# nrf7140_wificore register map
Vendor: Nordic Semiconductor; Series: nRF71; File version: 1
Registers are 32-bit, read-write, reset 0x0 unless marked. A register's access mark holds for its fields unless they carry their own. Offsets are from the block's base; [hi:lo] are bit positions; lines under a group give offsets from that group; {n}, {i} and the like mark numbered series; 'fields as' and 'values as' point back to an identical list; <NAME> marks a mode.

## RPUSYS (part 2 of 3) — RPUPBUS
Base 0x48080000; alternate view of RPUMAC
0x6000 EDC_PERIP group — Unspecified
  {0x0+0x20*j} EDCPERIPCHANREGS[{j}] (j=0..63) group — Unspecified
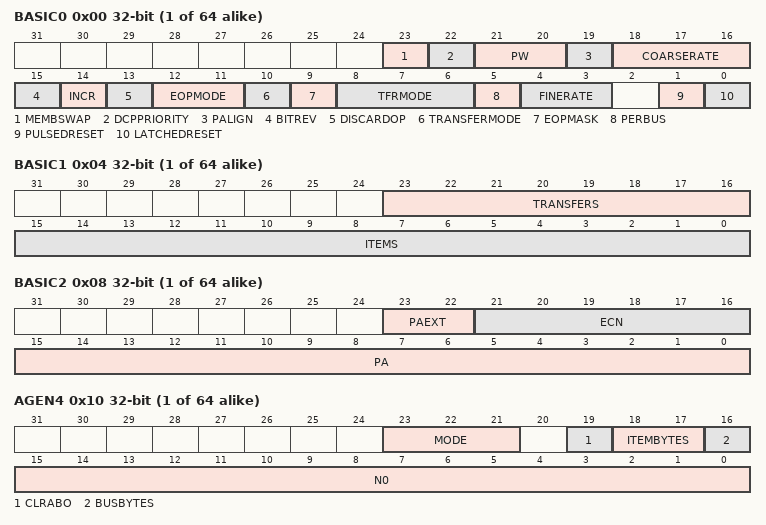
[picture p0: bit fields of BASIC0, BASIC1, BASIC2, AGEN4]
    0x00 BASIC0 — Description cluster: EDC PERIP BASIC0
      [23] MEMBSWAP — Big/little endian byte swap.If set, byte order will be reversed in all memory read/write transfers.MEM_BSWAP is applied on 24-bit GRAM or 32-bit External RAM memory accesses.MEM_BSWAP is applied on the memory word after the peripheral data to transfer has been packed, or on the memory word read from RAM before it is unpacked for transfer to the peripheral.Note : Applied to both source and destination memory transfers.
      [22] DCPPRIORITY — Specifies the priority of DCP thread execution:
        0=LowPriorityDcpThread; 1=High priority DCP thread (use for realtime peripherals such as the SCP)
      [21:20] PW — Specifies the width of the peripheral transfer.If transfers are being performed on the wide Tbus then parallel transfers of this width take place.
        0=8BitPbusOrTbus; 1=16BitPbusOrTbus; 2=24BitPbusOrTbus; 3=32BitSysbus
      [19] PALIGN — Specifies the alignment of peripheral data:
        0=DataIsRightAligned; 1=DataIsLeftAligned
      [18:16] COARSERATE — COARSE_RATE defines the rate at which EDC_BURST_LENGTH byte bursts may be transferred on this channel.0 : CR = 1 / 81 : CR = 1 / 162 : CR = 1 / 323 : CR = 1 / 644 : CR = 1 / 1285 : CR = 1 / 2566 : CR = 1 / 5127 : CR = 1 / 1024FR bursts every CR sysclk periods, giving (sysclk * EDC_BURST_LENGTH * FR * CR) bytes / sec)Notes:1. If COARSE_RATE=0 and FINE_RATE=0 then the burst rate is not controlled.2. COARSE_RATE is unused for TFR_MODE=100,101, where the COARSE_RATE for the ECN linked channel with TFR_MODE=001,011 is used once for both transfers.
      [15] BITREV — Specifies bit reversal within transferred bytes:0 : Bytes are not bit reversed1 : Bytes are bit reversedNotes :1. Applied to destination transfers only.2. Just the parameter for the destination channel is used when linked using ECN.
      [14] INCR — Specifies incrementing peripheral address burst mode.By default all operations to the peripheral are to a single register location.Note: Only applicable to SysBus or PBus transfers.
        0=Static peripheral address defined by PA.Typically used when transferring to/from a FIFO mapped to a single data port peripheral address; 1=Incrementing peripheral address, start address defined by PA. Typically used when transferring to a block of configuration registers.
      [13] DISCARDOP — Controls whether output of transfers should be discarded:0 : Output not discarded.1 : Output discarded, transfers otherwise operate as normal.Notes:1. this control cannot be used for 'to EDC channel (ECN)' transfers where it should instead be set for the 'from EDC channel (ECN)' transfer.2. this register is double buffered at start of job.
      [12:11] EOPMODE — Specifies the end of packet mode:Notes: 1. When enabled, EOP signal terminates all TRANSFERS, not just ITEMS within current transfer.
        0=DMA job completes after TRANSFERS*ITEMS transfers; 1=Reserve (This is reserved.); 2=DmaJobCompletesAfter2 (DMA job completes after TRANSFERS*ITEMS transfers, or on receipt of EOP signal from peripheral, whichever occurs first.); 3=Reserve3 (This is reserved.)
      [10] TRANSFERMODE — Selects multiple 16-bit items length or single 24-bit items length transfer:0 : Perform TRANSFERS * ITEMS item transfers.1 : Perform single '(TRANSFERS << 16) | ITEMS' item transfer.Notes:1. TRANSFERS_MODE must be written before writing TRANSFERS and ITEMS to BASIC1.2. TRANSFERS will always return 1 after switching TRANSFERS_MODE from 1 to 0.3. Single 24-bit items length transfer supported only when address generator is in row-column mode. Note that row-column mode is available only when EDC_SYS_CONFIGURATION_STATUS[0] = '1'; therefore 24-bit items transferis supported only when EDC_SYS_CONFIGURATION_STATUS[0] = '1'.The required row-column parameters to have modulo addressing are N0=anything that divides N2 and such that N0 >= GRAM_REQS-1 (the second condition is required to have best performance), N1=1, N2=modulo, A=0, B=0, O=start index.
      [9] EOPMASK — Selects the mask for the last memory write in case of EOP:
        0=Mask from address generator is used; 1=Mask from TBus read port is used
      [8:6] TFRMODE — 000 : Read from memory (MA+agenOffset), write to peripheral (PA+incrOffset)001 : Read from memory(MA+agenOffset), write to EDC channel (ECN)010 : Read from peripheral (PA+incrOffset), write to memory (MA+agenOffset)011 : Read from peripheral (PA+incrOffset), write to EDC channel (ECN)100 : Read from EDC channel (ECN), write to memory (MA+agenOffset)101 : Read from EDC channel (ECN), write to peripheral (PA+incrOffset)110 : Read FDSG/LFSR/PRBS offsets from MMR (MA+[0:3]), write to transfer bus (TBus)111 : Read from peripheral (PA+incrOffset), write to peripheral (MA+incr2Offset)Notes: 1. ITEMS must match for peripheral to peripheral transfers.2. Partial address masks only supported at end of transfers.3. 'from EDC channel (ECN)' transfers should be configured/started before 'to EDC channel (ECN)' transfers.4. ITEM_BYTES must be set to 3 bytes for TFR_MODE=110
      [5] PERBUS — Selects bus for peripheral transfers:0 : Peripheral transfer is carried over the transfer bus (TBus) using hardware flow control of peripheral accesses.1 : Peripheral transfer is carried over the non-stalling peripheral bus (SysBus or PBus) using (PA + incrOffset) as the peripheral addressNotes:1. Must be set to 0 when TFR_MODE=110.2. Must be set to 1 when PW=11.
      [4:3] FINERATE — COARSE_RATE and FINE_RATE together define the rate at which EDC_BURST_LENGTH byte bursts may be transferred on this channel.0 : FR = 71 : FR = 62 : FR = 53 : FR = 4FR bursts every CR sysclk periods, giving (sysclk * EDC_BURST_LENGTH * FR * CR) bytes / sec)Notes:1. If COARSE_RATE=0 and FINE_RATE=0 then the burst rate is not controlled.2. COARSE_RATE is unused for TFR_MODE=100,101, where the COARSE_RATE for the ECN linked channel with TFR_MODE=001,011 is used once for both transfers.
      [1] PULSEDRESET — Pulsed channel transfer engine software reset, clears automatically at start of next transfer on channel.Note: Once set must remain high before a DCP start/run instruction, so if set before ldbasic/ldfull it must be set again by the ldbasic/ldfull before the start/run.
      [0] LATCHEDRESET — Latched transfer engine channel software reset.Note: Use of PULSED_RESET is preferred over LATCHED_RESET.
    0x04 BASIC1 — Description cluster: EDC PERIP BASIC1
      [23:16] TRANSFERS — When TRANSFERS_MODE=0:The number of DMA transfers in the DMA job, represented in 'natural' format (TRANSFERS=1 specifies one transfer).TRANSFERS = 0 selects a different mode of operation -Skip the number of items defined by ITEMS, then generate one item without updating the state of the address generator.This mode is used for applying error correction to the Outer Decoder input data.When TRANSFERS_MODE=1:ITEMS[23:0] (TRANSFERS is internally fixed at 1).Note: when EOP_MODE = '10', TRANSFERS > 1 is not supported.
      [15:0] ITEMS — The number of items in each DMA transfer, represented in 'natural' format (ITEMS=1 gives one transfer).The total number of items in a DMA job is (TRANSFERS * ITEMS).If transferring to/from TBus peripherals, (ITEM_BYTES+1)*ITEMS must be divisible by (PW+1)*PERIP_NUM, with any surplus being discarded, and whilst a byte mask isprovided to TBus peripherals to indicate shortfall few peripherals make use of this.Decremented by 'ITEM_BYTES+1'.Note: This register is double buffered at start of job.
    0x08 BASIC2 — Description cluster: EDC PERIP BASIC2
      [23:22] PAEXT — Extended PA address bit.
      [21:16] ECN — When TFR_MODE=000 ... 110 :EDC channel number to connect with for memory-to-memory transferNote: When linking channels using ECN the ITEMS setting for each channel must match, though TRANSFERS need not be the same.This hardware restriction arises because each transfer consists of a sequence of EDC_BURST_LENGTH byte bursts,with one final burst which carries the number of bytes required to complete the transfer.The number of bytes in the final burst of a transfer is rem(ITEMS * (ITEM_BYTES+1), EDC_BURST_LENGTH).When TFR_MODE=111 :ECN[4:3]=PW_2 : Specifies the width of the destination peripheral transfer.If transfers are being performed on the wide Tbus then parallel transfers of this width take place.00 : 8 bit(PBus or TBus)01 : 16 bit (PBus or TBus)10 : 24 bit (PBus or TBus)11 : 32 bit (SysBus)ECN[2]=PALIGN_2 : Specifies the alignment of destination peripheral data:0 : Data is right aligned1 : Data is left alignedECN[1]=INCR_2 : Specifies incrementing destination peripheral address burst mode.By default all operations to the destination peripheral are to a single register location.0 : Static destination peripheral address defined by MA.Typically used when transferring to a FIFO mapped to a single data port destination peripheral address.1 : Incrementing destination peripheral address, start address defined by MA. Typically used when transferring to a block of configuration registers.Note: Only applicable to SysBus or PBus transfers.ECN[0]=PER_BUS_2 : Selects bus for destination peripheral transfers:0 : Destination peripheral transfer is carried over the transfer bus (TBus) using hardware flow control of destination peripheral accesses.1 : Destination peripheral transfer is carried over the non-stalling peripheral bus (SysBus or PBus) using (MA + incr2Offset) as the destination peripheral address
      [15:0] PA — For transfers over the non-stalling peripheral bus (SysBus or PBus), PA specifies the base peripheral address.For transfers over the stalling transfer bus (TBus), PA[13:0] selects the port ID within the following TBus read/write port selection groups:PA[15:14]=00 : Peripheral TBus write ports.PA[15:14]=01 : EDC Address Generator Offset write ports.PA[15:14]=10 : Peripheral TBus read portsNotes:1. INCR=1 produces a sequence of incrementing addressesPA, PA+1, PA+2, ...2. Address generator offset TBus write requests must be allocated to a higher priority (lower number) EDC channelthan the EDC channel address generator that they are feeding.3. Address generator offset TBus write requests EDC channel must be started before the EDC channel address generator that they are feeding.
    0x0C BASIC3 — Description cluster: EDC PERIP BASIC3
      [23:0] MA — When TFR_MODE=000 ... 110 :Memory Address defines the base address of the memory transfers controlled by this DMA channel.The units of MA are physical RAM locations, and the physical RAM bus targetted by this DMA channel is selected by BUS_BYTES. The byte address of the memory base in the chosen RAM space is MA * BUS_BYTES.When TFR_MODE=111 :For transfers over the non-stalling peripheral bus (SysBus or PBus), MA specifies the base peripheral address.For transfers over the stalling transfer bus (TBus), MA[13:0] selects the port ID within the following TBus write port selection groups:MA[15:14]=00 : Peripheral TBus write ports.MA[15:14]=01 : EDC Address Generator Offset write ports.Notes:1. INCR=1 produces a sequence of incrementing addressesMA, MA+1, MA+2, ... (where MA is shadowed for transfer rather than current MA used by DCP)2. Address generator offset TBus write requests must be allocated to a higher priority (lower number) EDC channelthan the EDC channel address generator that they are feeding.3. Address generator offset TBus write requests EDC channel must be started before the EDC channel address generator that they are feeding.4. This register is double buffered at start of job.
    0x10 AGEN4 — Description cluster: EDC PERIP AGEN4
      [23:21] MODE — Note: If EDC_SYS_CONFIGURATION_STATUS[0] = '0', only modulo mode is supported.
        0=Modulo; 1=RepeatSkip; 2=RowColumn; 3=TwistedRowColumn; 4=BurstRowColumn; 5=Fifo; 6=RunLength; 7=RowColCd
      [19] CLRABO — Setting CLR=1 clears the internal registers a, b and o in the address generator for this channel.This register clears automatically.
      [18:17] ITEMBYTES — The number of bytes in each item of the data structure accessed by the address generator.0 : 1 byte1 : 2 bytes2 : 3 bytes3 : 4 bytesNotes:1. This must be programmed correctly even when the address generator is not in use.2. This register is double buffered at start of job.
      [16] BUSBYTES — The byte width of the memory bus targetted by the address generator.Note: this register is double buffered at start of job.
        0=3BytesGlobalRamBus; 1=4 bytes (external RAM bus)
      [15:0] N0 — Address generator N0 parameter.Use depends on selected mode:Modulo mode : modulo (0 value gives 2^16 modulo)Repeat-skip mode: number of items in one sequenceRow-column mode : number of items in one block (rows * columns)Twisted row-column mode : number of items in one burstBurst row-column mode : number of items in one burstFIFO mode : number of items in one burst (one burst for each FIFO )Run-length mode : number of items to skip after one 'run'Row-column-CD mode: number of FIFOs
    0x14 AGEN5 — Description cluster: EDC PERIP AGEN5
      [23:0] N1 — Address generator N1 parameter.Use depends on EDC_SYS_CONFIGURATION_STATUS register and OFFSET_ADD field of EDC_PERIP_JOB0 register:If EDC_SYS_CONFIGURATION_STATUS[1] = '1' and OFFSET_ADD = '1' then only 10 LSBs are used and it represents the LUT read pointer. Automatically incremented. When LUT are used, address generator increment is not needed.Else use depends on selected mode:Modulo mode : increment per itemRepeat-skip mode: number of repeats of each sequenceRow-column mode : number of rowsTwisted row-column mode : number of rowsBurst row-column mode : number of rowsFIFO mode : number of FIFOsRun-length mode : unusedRow-column-CD mode: rem((d1-d0) * numFifos + buffLen, buffLen), where d0 is the delay of FIFO 0 and d1 is the delay of FIFO 1, both measured in itemsNotes:1. If EDC_SYS_CONFIGURATION_STATUS[1] = '1', this register is double buffered (only 10 LSBs) at start of job, to allow reconfiguration of LUT read pointer while job is still active.2. If EDC_SYS_CONFIGURATION_STATUS[1:0] = '00', this register is not present and the increment per item if fixed to 1.
    0x18 AGEN6 — Description cluster: EDC PERIP AGEN6
      [23:0] N2 — Address generator N2 parameter.Use depends on selected mode:Modulo mode : if AGEN_STATE_B[0]=0, start index (must be in the range 0 to N0-1), else unusedRepeat-skip mode: number of items from the start of one sequence to the start of the next sequenceRow-column mode : number of items in the set of blocks (rows * columns * blocks)Twisted row-column mode : number of items in one block(rows * columns)Burst row-column mode : number of items in one block minus number of items in one burst(rows * columns - N0)FIFO mode : number of items in the whole FIFO structureRun-length mode : unusedRow-column-CD mode: number of items in the CD buffer.Note: N2 must be an integer multiple of abs(d1-d0) * numFifos, where d0 is the delay of FIFO 0 and d1 is the delay of FIFO 1, both measured in itemsIf OFFSET_ADD is in use and EDC_SYS_CONFIGURATION_STATUS[1] = '1', N2 can be set to enforce a modulo on the LUT read pointer.Notes:1. This register is double buffered at start of job.2. If EDC_SYS_CONFIGURATION_STATUS[0] = '0', only 16 LSBs are used.
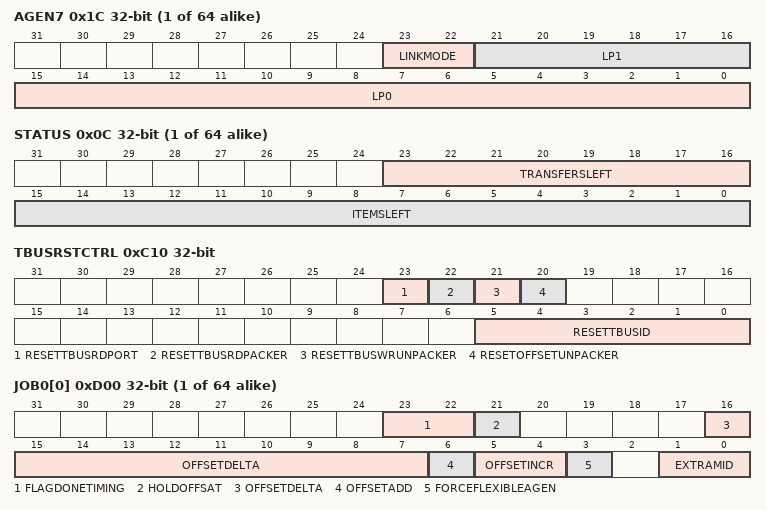
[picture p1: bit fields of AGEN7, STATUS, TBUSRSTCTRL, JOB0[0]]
    0x1C AGEN7 — Description cluster: EDC PERIP AGEN7
      [23:22] LINKMODE — Controls pairing of even numbered write channel 'N' and odd numbered read channel 'N+1':00 : Pairing disabled01 : Pair using FIFO mode10 : Pair using BLOCK mode11 : reservedNotes:1. Linked channels must have the same ITEM_BYTES configuration.2. LINK_MODE must be disabled on channels with EXT_RAM_READ_AHEAD set to 1(but can be set on channels ECN linked to these that have EXT_RAM_READ_AHEAD set to 0).3. Changing LINK_MODE setting causes read and write buffer counts to be reset.4. If EDC_SYS_CONFIGURATION_STATUS[0] = '0', the pairing is not supported.
      [21:16] LP1 — FIFO mode: not usedBLOCK mode : maxBlocks - the maximum number of blocks in a paired buffer
      [15:0] LP0 — FIFO mode: maxItems - the maximum number of items in a paired bufferNote: If read ITEMS is not equal to write ITEMS then LP0 must be >= 2 * EDC_BURST_LENGTHBLOCK mode : itemsPerBlock - the number of items in a block
  {0x800+0x10*j} EDCPERIPCTXTREGS[{j}] (j=0..63) group — Unspecified
    0x00 AGENCONTEXT0 — Description cluster: EDC PERIP AGEN CONTEXT0
      [15:0] AGENSTATEA — Address generator A variable.If this register is loaded by the DCP then it should be fenced using LDBASIC/LDFULL before the RUN instruction.
    0x04 AGENCONTEXT1 — Description cluster: EDC PERIP AGEN CONTEXT1
      [15:0] AGENSTATEB — Address generator B variable.If MODE=0 (modulo mode) AGEN_STATE_B[0]=1 causes N2 to be substituted with offsets fed from another channel.If AGEN_STATE_B[0]=1, N1 must be different than 1 to prevent linear mode logic to be enabled, since it does not support offset addition.If this register is loaded by the DCP then it should be fenced using LDBASIC/LDFULL before the RUN instruction.
    0x08 AGENCONTEXT2 — Description cluster: EDC PERIP AGEN CONTEXT2
      [23:0] AGENSTATEO — Address generator O variable.If this register is loaded by the DCP then it should be fenced using LDBASIC/LDFULL before the RUN instruction.
    0x0C STATUS — Description cluster: EDC PERIP STATUS
      [23:16] TRANSFERSLEFT — When TRANSFERS_MODE=0:The number of DMA transfers remaining in the DMA job, represented in 'natural' format.When TRANSFERS_MODE=1:ITEMS_LEFT[23:0].
      [15:0] ITEMSLEFT — The number of items remaining in each DMA transfer, represented in 'natural' format.Note: This is updated to represent the number of items completed when a job completes for EOP_MODE=10.
  0xC00 EDCGPIO0OUT
    [15:0] GPIO0OUT — Value output on bits 15:0 of UCCP top level GPIO_OUT pins.
  0xC04 EDCGPIO1OUT
    [15:0] GPIO1OUT — Value output on bits 31:16 of UCCP top level GPIO_OUT pins.
  0xC08 EDCGPIO0IN ro
    [15:0] GPIO0IN — Value input on bits 15:0 of UCCP top level GPIO_IN pins.
  0xC0C EDCGPIO1IN ro
    [15:0] GPIO1IN — Value input on bits 31:16 of UCCP top level GPIO_IN pins.
  0xC10 TBUSRSTCTRL — EDC PERIP TBUS RST CTRL
    [23] RESETTBUSRDPORT — Reset TBus read port data held for next transfer.
    [22] RESETTBUSRDPACKER — Reset TBus read packer.
    [21] RESETTBUSWRUNPACKER — Reset TBus write unpacker.
    [20] RESETOFFSETUNPACKER — Reset Address Generator Offset unpacker.
    [5:0] RESETTBUSID — Port ID of TBus to reset.
  0xC14 PERFCTRL — EDC PERIP PERF CTRL
    [23] EXTRAMREADAHEAD — 0 : Do not read-ahead from ExtRAM (appropriate setting for multi-channel ExtRAM reads).1 : Read-ahead from ExtRAM (appropriate setting for single-channel ExtRAM reads or multi-channel only where each channel has a unique EXT_RAM_ID in range 0 to EDC_EXT_RAM_REQS-1).For use in high read latency ExtRAM systems, should not be used in low latency ExtRAM systems as can reduce performance due to additional destination address generation latency.When enabled, address generator modes that make use of offsets (run-length, twisted-row-col, FIFO) are not supported for ExtRAM or GRAM TFR_MODE=4 destination transfer from an ExtRAM source TFR_MODE=1 transfer.ExtRAM-to-ExtRAM transfers are not supported when enabled.
  0xC18 EDCSCPCTRL
    [11:0] EDCSCPKICK — EDC_SCP_KICK[n]=1 causes update of SET_ADC_POWER/SET_SCP_POWER/NEW_ADC_POWER/NEW_SCP_POWER/INPUT_I/INPUT_Q registers within SCP[n] when SCP_CONTROL2[n].SCP_KICK_ENABLE=1.Register auto-clears.
  0xC1C EDCDCPBASEADDR
    [23:0] DCPBASEADDR — Base address of combined DCP code image (for use by debugger).
  0xC20 WLANRXCTRL — EDC PERIP WLAN RX CTRL
    [8] WLANRXFINAL — Set to flag last Rx Job before posting final SCP input transfer.Must be cleared following completion of SCP input job.
  0xC24 WLANTXCTRL — EDC PERIP WLAN TX CTRL
    [8] WLANTXFINAL — Set to flag last Tx Job before posting final TX-SCP output transfer.Must be cleared following completion of TX-SCP output job.
  {0xC2C+4j} MEMADDRMSBS{j} (j=0..3) — EDC PERIP MEM ADDR MSBS{j}
    [14:0] EXTRAMID{j}ADDRMSBS — Defines bits 37:23 of ExtRAM request ID {j} word address (bits 39:25 of the byte address).Note if greater than 64MBytes ExtRAM supported, MA[23] must be set to 0 and the lsb of this register used instead.
  {0xC3C+4j} MEMADDRMSBSEXT{j} (j=0..3) — EDC PERIP MEM ADDR MSBS EXT{j}
    [23:0] EXTRAMID{j}ADDRMSBSEXT — Defines bits 61:38 of ExtRAM request ID {j} word address (bits 63:40 of the byte address).Note if greater than 64MBytes ExtRAM supported, MA[23] must be set to 0 and the lsb of this register used instead.
  {0xD00+4j} JOB0[{j}] (j=0..63) — Description collection: EDC PERIP JOB0
    [23:22] FLAGDONETIMING — Note: Channel DISCARD_OP/PW/PALIGN settings cannot be changed safely following completion of a TBus write job when FLAG_DONE_EARLY=1 because these are used following the output buffer.
      0=Flag completion of TBus write job on output to peripheral; 1=FlagCompletionOfTbus1 (Flag completion of TBus write job on write to output buffer, providing additional time to configure subsequent jobs for realtime output peripherals (e.g. DAC, TSO).); 2=Flag completion of transfer to ExtRAM/GRAM/PBus/SysBus only once final store has reached destination.This could impact performance.Not supported for write to EDC channel or write to TBus transfer modes (TFR_MODE=001,011,110 or TFR_MODE=000,101,111 && PER_BUS=0)
    [21] HOLDOFFSAT — Indicates that the transfer hold-off FINE_RATE accumulator has saturated.Automatically cleared at start of next DMA job.
    [16:7] OFFSETDELTA — Defines the delta to be added to MA in case of GRAM accesses with OFFSET_ADD = 1 and OFFSET_INCR > 0.Note: This feature can be used only if EDC_SYS_CONFIGURATION_STATUS[1] = '1'.
    [6] OFFSETADD — 0: Disable addition of offsets to GRAM addresses.1: Enable addition of offsets to GRAM addresses.Notes:1. This feature can be used only if EDC_SYS_CONFIGURATION_STATUS[1] = '1'.2. Only ITEM_BYTES = '10' is supported.3. Modulo wrap of item index is not supported.
    [5:4] OFFSETINCR — Note: This feature can be used only if EDC_SYS_CONFIGURATION_STATUS[1] = '1'.
      0=Advance offset every GRAM access; 1=Advance offset every 2 GRAM accesses; 2=Advance offset every 4 GRAM accesses; 3=Advance offset every 8 GRAM accesses
    [3] FORCEFLEXIBLEAGEN — Note: if EDC_SYS_CONFIGURATION_STATUS[0] = '0', this register is notpresent.
      0=Do not use flexible address generator when linear mode is configured; 1=Force usage of flexible address generator (over linear address generator) even if linear mode is configured
    [1:0] EXTRAMID — ExtRAM request ID used for ExtRAM transfers on this channel.Note: DCP uses ID of 0 for instruction fetch and loads/stores.
  0xE00 EDCOFFSETLUTADDR
    [15:0] OFFSETLUTADDR — Offset lookup table address. Automatically incremented when all the entries (number of entries per location = GRAM_REQS-1) at the same address have been written.Note: This feature can be used only if EDC_SYS_CONFIGURATION_STATUS[2] = '1'.
  0xE04 EDCOFFSETLUTDATA
    [19:0] OFFSETLUTDATA — Offset lookup table value to be written into the offset LUT.Note: This feature can be used only if EDC_SYS_CONFIGURATION_STATUS[2] = '1'.
  0xE08 EDCOFFSETADJLUTADDR
    [15:0] OFFSETADJLUTADDR — Offset adjustment lookup table address. Automatically incremented.Note: This feature can be used only if EDC_SYS_CONFIGURATION_STATUS[2] = '1'.
  0xE0C EDCOFFSETADJLUTDATA
    [0] OFFSETADJLUTDATA — Offset adjustment lookup table value to be written into the offset adjustment LUT.Note: This feature can be used only if EDC_SYS_CONFIGURATION_STATUS[2] = '1'.
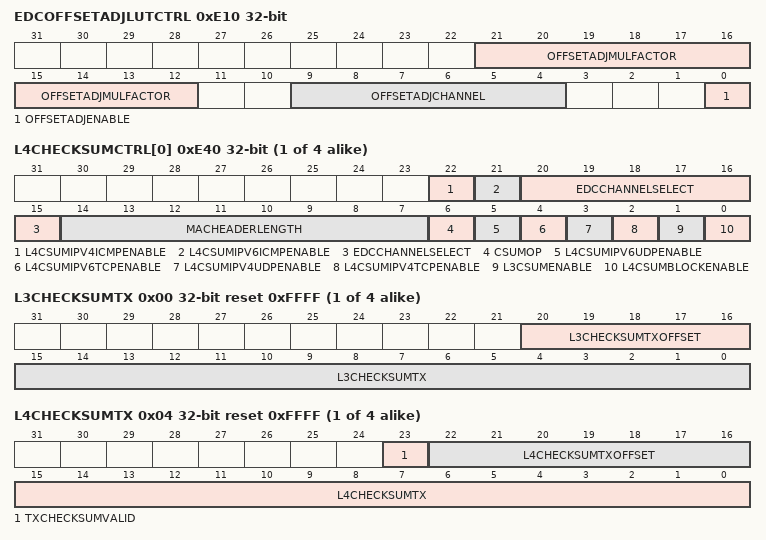
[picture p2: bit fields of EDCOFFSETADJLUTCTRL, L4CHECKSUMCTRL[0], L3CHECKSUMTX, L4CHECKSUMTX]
  0xE10 EDCOFFSETADJLUTCTRL
    [21:12] OFFSETADJMULFACTOR — Defines the multiplication factor used for the offset adjustments.Note: This feature can be used only if EDC_SYS_CONFIGURATION_STATUS[2] = '1'.
    [9:4] OFFSETADJCHANNEL — Select which EDC channel the offset adjustments are applied to.Note: Selected EDC channel must be configured for offset addressing OFFSET_ADD=1.
    [0] OFFSETADJENABLE — Note: This feature can be used only if EDC_SYS_CONFIGURATION_STATUS[2] = '1'.
      0=Disable addition of offset adjustments to GRAM addresses; 1=Enable addition of offset adjustments to GRAM addresses
  {0xE40+4j} L4CHECKSUMCTRL[{j}] (j=0..3) — Description collection: EDC PERIP L4 CHECKSUM CTRL
    [22] L4CSUMIPV4ICMPENABLE — Enable signal for L4 checksum calculation in case of IPV4 ethernet type and ICMP protocol:
      0=L4 checksum calculation disabled,; 1=L4ChecksumCalculatio1 (L4 checksum calculation enabled.)
    [21] L4CSUMIPV6ICMPENABLE — Enable signal for L4 checksum calculation in case of IPV6 ethernet type and ICMP protocol:
      values as L4CSUMIPV4ICMPENABLE
    [20:15] EDCCHANNELSELECT — EDC channel select.Selects the EDC channel connected to L4 checksum instance.
    [14:7] MACHEADERLENGTH — MAC header length in bytes.This is the number of bytes at the start of packet that are skipped and notincluded in the L4 checksum calulation.Note: only even values for MAC header lengths are supported.
    [6] CSUMOP — L4 checksum operation:0:TX operation. L3 and L4 checksums are calculated,1:RX operation. L3 and L4 checksums are calculated and compared with thecorresponding received checksum values.
    [5] L4CSUMIPV6UDPENABLE — Enable signal for L4 checksum calculation in case of IPV6 ethernet type and UDP protocol:
      values as L4CSUMIPV4ICMPENABLE
    [4] L4CSUMIPV6TCPENABLE — Enable signal for L4 checksum calculation in case of IPV6 ethernet type and TCP protocol:
      values as L4CSUMIPV4ICMPENABLE
    [3] L4CSUMIPV4UDPENABLE — Enable signal for L4 checksum calculation in case of IPV4 ethernet type and UDP protocol:
      values as L4CSUMIPV4ICMPENABLE
    [2] L4CSUMIPV4TCPENABLE — Enable signal for L4 checksum calculation in case of IPV4 ethernet type and TCP protocol:
      values as L4CSUMIPV4ICMPENABLE
    [1] L3CSUMENABLE — Enable signal for L3 checksum calculation in case of IPV4 ethernet type:
      0=L3 checksum calculation disabled,; 1=L3ChecksumCalculatio1 (L3 checksum calculation enabled.)
    [0] L4CSUMBLOCKENABLE — Enable signal for L4 checksum block:
      0=L4 checksum block disabled,; 1=L3 checksum block enabled
  {0xE50+0xC*j} EDCPERIPL4CHECKSUMSTATUS[{j}] (j=0..3) group — Unspecified
    0x00 L3CHECKSUMTX ro reset 0xFFFF — Description cluster: EDC PERIP L3 CHECKSUM TX
      [20:16] L3CHECKSUMTXOFFSET — L3 checksum TX offset.This field gives the information on offset of L3 checksum within the packet.
      [15:0] L3CHECKSUMTX — Calculated L3 checksum.Note: L3 checksum is calculated only for IPV4 ethernet type.This register will hold calculated L3 checksum value for both operations TX and RX andit will be cleared at the start of every new packet.Note: This field should be read once the TX_CHECKSUM_VALID flag is asserted in TX operation.In RX operation this value can be used for debug and checked after RX_CHECKSUM_VALID flag assertion.
    0x04 L4CHECKSUMTX ro reset 0xFFFF — Description cluster: EDC PERIP L4 CHECKSUM TX
      [23] TXCHECKSUMVALID — TX checksum valid flag.This bit gets set once the L4 checksum calculation for TX operation is completedand it will be cleared at the start of every new packet.
      [22:16] L4CHECKSUMTXOFFSET — L4 checksum TX offset.This field gives the information on offset of L4 checksum within the packet.
      [15:0] L4CHECKSUMTX — Calculated L4 checksum.This field will hold calculated L4 checksum value for both operations TX and RXand it will be cleared at the start of every new packet.Note: This field should be read once the TX_CHECKSUM_VALID flag is asserted in TX operation.In RX operation this value can be used for debug and checked after RX_CHECKSUM_VALID flag assertion.
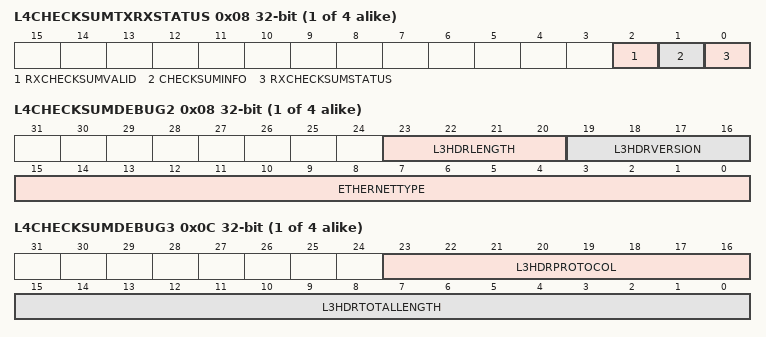
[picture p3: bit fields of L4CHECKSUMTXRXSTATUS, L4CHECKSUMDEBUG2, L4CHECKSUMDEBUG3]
    0x08 L4CHECKSUMTXRXSTATUS ro — Description cluster: EDC PERIP L4 CHECKSUM TX RX STATUS
      [2] RXCHECKSUMVALID — RX checksum valid flag.This bit gets set once the L4 checksum calculation for RX operation is completedand L4 checksum status is ready. It will be cleared at the start of every new packet.
      [1] CHECKSUMINFO — TX_RX checksum info flag.Note: This bit is used for both TX and RX operation.It will be cleared at the start of every new packet.
        0=Calculation of L4 checksum was skipped,; 1=L4 checksum calculated and was not skipped
      [0] RXCHECKSUMSTATUS — RX checksum status flag.Note: This bit should be checked once the RX_CHECKSUM_VALID flag is asserted.It will be cleared at the start of every new packet.
        0=FAIL - Calculated L4 checksum and L4 checksum extracted from packet header are mismatching,; 1=PASS - Calculated L4 checksum and L4 checksum extracted from packet header are matching
  {0xE90+0x10*j} EDCPERIPL4CHECKSUMDEBUG[{j}] (j=0..3) group — Unspecified
    0x00 L4CHECKSUMDEBUG0 ro — Description cluster: EDC PERIP L4 CHECKSUM DEBUG0
      [15:0] L3HDRCHECKSUM — L3 checksum extracted from the packet.This field will be cleared at the start of every new packet.
    0x04 L4CHECKSUMDEBUG1 ro — Description cluster: EDC PERIP L4 CHECKSUM DEBUG1
      [15:0] L4HDRCHECKSUM — L4 checksum extracted from the packet.This field will be cleared at the start of every new packet.
    0x08 L4CHECKSUMDEBUG2 ro — Description cluster: EDC PERIP L4 CHECKSUM DEBUG2
      [23:20] L3HDRLENGTH — Length of the IP header in 32 bit words extracted from the packet.For example value 5 means 5*4 = 20 bytes.This field will be cleared at the start of every new packet.
      [19:16] L3HDRVERSION — Protocol Version extracted from the packet.This field will be cleared at the start of every new packet.
      [15:0] ETHERNETTYPE — Ethernet type information extracted from the packet.This field will be cleared at the start of every new packet.
    0x0C L4CHECKSUMDEBUG3 ro — Description cluster: EDC PERIP L4 CHECKSUM DEBUG3
      [23:16] L3HDRPROTOCOL — Transport layer protocol information extracted from the packet.This field will be cleared at the start of every new packet.
      [15:0] L3HDRTOTALLENGTH — Total length of packet in bytes extracted from the packet.Note: In case of IPV4 ethernet type this field is the sum of the IP header lengthL3_HDR_LENGTH and the IP payload length.In case of IPV6 ethernet type this field represents the IP payload length only.This field will be cleared at the start of every new packet.
  {0xF00+0x40*j} EDCPERIPL4CHECKSUMSRCDESTADDRESS[{j}] (j=0..3) group — Unspecified
    0x00 L4CHECKSUMSRCADDR0LSH ro — Description cluster: EDC PERIP L4 CHECKSUM SRC ADDR0 LSH
      [15:0] L3HDRSRCADDR0LSH — Part of the Source Address field extracted from the packet.This field represents least significant 16 bits of first 32 bit word andit will be cleared at the start of every new packet.
    0x04 L4CHECKSUMSRCADDR0MSH ro — Description cluster: EDC PERIP L4 CHECKSUM SRC ADDR0 MSH
      [15:0] L3HDRSRCADDR0MSH — Part of the Source Address field extracted from the packet.This field represents most significant 16 bits of first 32 bit word andit will be cleared at the start of every new packet.
    0x08 L4CHECKSUMSRCADDR1LSH ro — Description cluster: EDC PERIP L4 CHECKSUM SRC ADDR1 LSH
      [15:0] L3HDRSRCADDR1LSH — Part of the Source Address field extracted from the packet.This field represents least significant 16 bits of second 32 bit word andit will be cleared at the start of every new packet.
    0x0C L4CHECKSUMSRCADDR1MSH ro — Description cluster: EDC PERIP L4 CHECKSUM SRC ADDR1 MSH
      [15:0] L3HDRSRCADDR1MSH — Part of the Source Address field extracted from the packet.This field represents most significant 16 bits of second 32 bit word andit will be cleared at the start of every new packet.
    0x10 L4CHECKSUMSRCADDR2LSH ro — Description cluster: EDC PERIP L4 CHECKSUM SRC ADDR2 LSH
      [15:0] L3HDRSRCADDR2LSH — Part of the Source Address field extracted from the packet.This field represents least significant 16 bits of third 32 bit word andit will be cleared at the start of every new packet.
    0x14 L4CHECKSUMSRCADDR2MSH ro — Description cluster: EDC PERIP L4 CHECKSUM SRC ADDR2 MSH
      [15:0] L3HDRSRCADDR2MSH — Part of the Source Address field extracted from the packet.This field represents most significant 16 bits of third 32 bit word andit will be cleared at the start of every new packet.
    0x18 L4CHECKSUMSRCADDR3LSH ro — Description cluster: EDC PERIP L4 CHECKSUM SRC ADDR3 LSH
      [15:0] L3HDRSRCADDR3LSH — Part of the Source Address field extracted from the packet.This field represents least significant 16 bits of fourth 32 bit word andit will be cleared at the start of every new packet.
    0x1C L4CHECKSUMSRCADDR3MSH ro — Description cluster: EDC PERIP L4 CHECKSUM SRC ADDR3 MSH
      [15:0] L3HDRSRCADDR3MSH — Part of the Source Address field extracted from the packet.This field represents most significant 16 bits of fourth 32 bit word andit will be cleared at the start of every new packet.
    0x20 L4CHECKSUMDSTADDR0LSH ro — Description cluster: EDC PERIP L4 CHECKSUM DST ADDR0 LSH
      [15:0] L3HDRDSTADDR0LSH — Part of the Destination Address field extracted from the packet.This field represents least significant 16 bits of first 32 bit word andit will be cleared at the start of every new packet.
    0x24 L4CHECKSUMDSTADDR0MSH ro — Description cluster: EDC PERIP L4 CHECKSUM DST ADDR0 MSH
      [15:0] L3HDRDSTADDR0MSH — Part of the Destination Address field extracted from the packet.This field represents most significant 16 bits of first 32 bit word andit will be cleared at the start of every new packet.
    0x28 L4CHECKSUMDSTADDR1LSH ro — Description cluster: EDC PERIP L4 CHECKSUM DST ADDR1 LSH
      [15:0] L3HDRDSTADDR1LSH — Part of the Destination Address field extracted from the packet.This field represents least significant 16 bits of second 32 bit word andit will be cleared at the start of every new packet.
    0x2C L4CHECKSUMDSTADDR1MSH ro — Description cluster: EDC PERIP L4 CHECKSUM DST ADDR1 MSH
      [15:0] L3HDRDSTADDR1MSH — Part of the Destination Address field extracted from the packet.This field represents most significant 16 bits of second 32 bit word andit will be cleared at the start of every new packet.
    0x30 L4CHECKSUMDSTADDR2LSH ro — Description cluster: EDC PERIP L4 CHECKSUM DST ADDR2 LSH
      [15:0] L3HDRDSTADDR2LSH — Part of the Destination Address field extracted from the packet.This field represents least significant 16 bits of third 32 bit word andit will be cleared at the start of every new packet.
    0x34 L4CHECKSUMDSTADDR2MSH ro — Description cluster: EDC PERIP L4 CHECKSUM DST ADDR2 MSH
      [15:0] L3HDRDSTADDR2MSH — Part of the Destination Address field extracted from the packet.This field represents most significant 16 bits of third 32 bit word andit will be cleared at the start of every new packet.
    0x38 L4CHECKSUMDSTADDR3LSH ro — Description cluster: EDC PERIP L4 CHECKSUM DST ADDR3 LSH
      [15:0] L3HDRDSTADDR3LSH — Part of the Destination Address field extracted from the packet.This field represents least significant 16 bits of fourth 32 bit word andit will be cleared at the start of every new packet.
    0x3C L4CHECKSUMDSTADDR3MSH ro — Description cluster: EDC PERIP L4 CHECKSUM DST ADDR3 MSH
      [15:0] L3HDRDSTADDR3MSH — Part of the Destination Address field extracted from the packet.This field represents most significant 16 bits of fourth 32 bit word andit will be cleared at the start of every new packet.
